VERSION ""

NS_ :

BS_:

BU_:

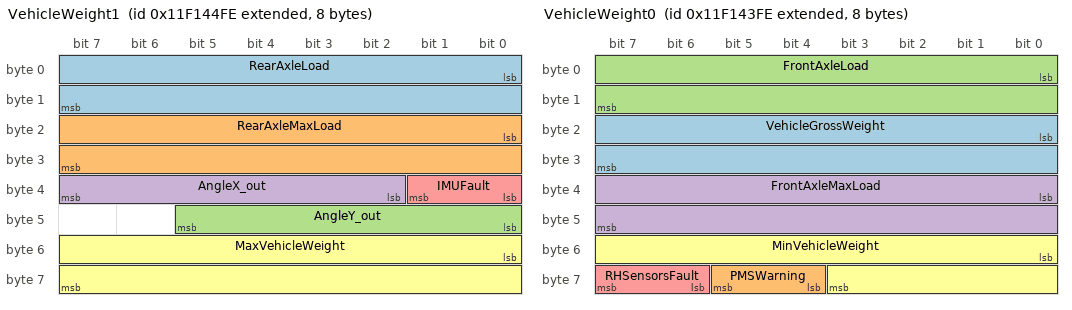
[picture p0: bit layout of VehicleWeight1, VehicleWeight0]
BO_ 2448508158 VehicleWeight1: 8 Vector__XXX
 SG_ RearAxleLoad : 0|16@1+ (1,0) [0|65535] "kg" Vector__XXX
 SG_ RearAxleMaxLoad : 16|16@1+ (1,0) [0|65535] "kg" Vector__XXX
 SG_ AngleY_out : 40|6@1+ (1.5,-45) [-45|45] "deg" Vector__XXX
 SG_ AngleX_out : 34|6@1+ (1.5,-45) [-45|45] "deg" Vector__XXX
 SG_ IMUFault : 32|2@1+ (1,0) [0|3] "" Vector__XXX
 SG_ MaxVehicleWeight : 48|16@1+ (1,0) [0|65535] "kg" Vector__XXX

BO_ 2448507902 VehicleWeight0: 8 Vector__XXX
 SG_ VehicleGrossWeight : 16|16@1+ (1,0) [0|65535] "kg" Vector__XXX
 SG_ PMSWarning : 60|2@1+ (1,0) [0|3] "" Vector__XXX
 SG_ FrontAxleLoad : 0|16@1+ (1,0) [0|65535] "kg" Vector__XXX
 SG_ FrontAxleMaxLoad : 32|16@1+ (1,0) [0|65535] "kg" Vector__XXX
 SG_ RHSensorsFault : 62|2@1+ (1,0) [0|3] "" Vector__XXX
 SG_ MinVehicleWeight : 48|12@1+ (10,0) [0|40000] "kg" Vector__XXX

CM_ BO_ 2448508158 "Vehicle Weight message with processed IMU  information from Payload Management";
CM_ SG_ 2448508158 IMUFault "Status of data flow from IMU";
CM_ BO_ 2448507902 "Vehicle Weight message with VGW information from Payload Management";
CM_ SG_ 2448507902 VehicleGrossWeight "Minimum value from ride height sensors measured on axles including distance unsprung mass";
CM_ SG_ 2448507902 PMSWarning "Figure of merit for ride height measurement.

00 - Ride height fully functional.  Data is within sensor specification. 
01 - Ride height degraded.  Data is suspect due to environmental conditions.
10 - Error
11 - Not available";
CM_ SG_ 2448507902 RHSensorsFault "Status of data flow from Ride Height Sensors";
BA_DEF_ SG_  "SigType" ENUM  "Default","Range","RangeSigned","ASCII","Discrete","Control","ReferencePGN","DTC","StringDelimiter","StringLength","StringLengthControl","MessageCounter","MessageChecksum";
BA_DEF_ SG_  "GenSigEVName" STRING ;
BA_DEF_ SG_  "GenSigILSupport" ENUM  "No","Yes";
BA_DEF_ SG_  "GenSigSendType" ENUM  "Cyclic","OnWrite","OnWriteWithRepetition","OnChange","OnChangeWithRepetition","IfActive","IfActiveWithRepetition","NoSigSendType";
BA_DEF_ SG_  "GenSigStartValue" INT 0 2147483647;
BA_DEF_ BO_  "GenMsgILSupport" ENUM  "No","Yes";
BA_DEF_ BU_  "NmStationAddress" INT 0 255;
BA_DEF_ BO_  "GenMsgSendType" ENUM  "cyclic","NotUsed","IfActive","NotUsed","NotUsed","NotUsed","NotUsed","NotUsed","noMsgSendType";
BA_DEF_ BO_  "GenMsgRequestable" INT 0 1;
BA_DEF_ BO_  "GenMsgCycleTime" INT 0 3600000;
BA_DEF_  "DBName" STRING ;
BA_DEF_  "BusType" STRING ;
BA_DEF_  "ProtocolType" STRING ;
BA_DEF_ BO_  "VFrameFormat" ENUM  "StandardCAN","ExtendedCAN","reserved","J1939PG";
BA_DEF_ BO_  "Producer" STRING ;
BA_DEF_DEF_ "Producer" "SCS" ;
BA_DEF_DEF_  "SigType" "Default";
BA_DEF_DEF_  "GenSigEVName" "Env@Nodename_@Signame";
BA_DEF_DEF_  "GenSigILSupport" "Yes";
BA_DEF_DEF_  "GenSigSendType" "NoSigSendType";
BA_DEF_DEF_  "GenSigStartValue" 0;
BA_DEF_DEF_  "GenMsgILSupport" "Yes";
BA_DEF_DEF_  "NmStationAddress" 254;
BA_DEF_DEF_  "GenMsgSendType" "noMsgSendType";
BA_DEF_DEF_  "GenMsgRequestable" 1;
BA_DEF_DEF_  "GenMsgCycleTime" 0;
BA_DEF_DEF_  "DBName" "";
BA_DEF_DEF_  "BusType" "CAN";
BA_DEF_DEF_  "ProtocolType" "J1939";
BA_DEF_DEF_  "VFrameFormat" "J1939PG";
BA_ "DBName" "Payload";
BA_ "GenMsgSendType" BO_ 2448508158 0;
BA_ "GenMsgCycleTime" BO_ 2448508158 100;
BA_ "GenMsgSendType" BO_ 2448507902 0;
BA_ "GenMsgCycleTime" BO_ 2448507902 100;
BA_ "GenSigStartValue" SG_ 2448508158 AngleY_out 30;
BA_ "GenSigStartValue" SG_ 2448508158 AngleX_out 30;
VAL_ 2448508158 IMUFault 3 "NA" 2 "Reserved" 1 "IMU Fault" 0 "Ok" ;
VAL_ 2448507902 PMSWarning 3 "NA" 2 "Fault" 1 "Active" 0 "Off" ;
VAL_ 2448507902 RHSensorsFault 3 "NA" 2 "Reserved" 1 "RH Fault" 0 "Ok" ;
